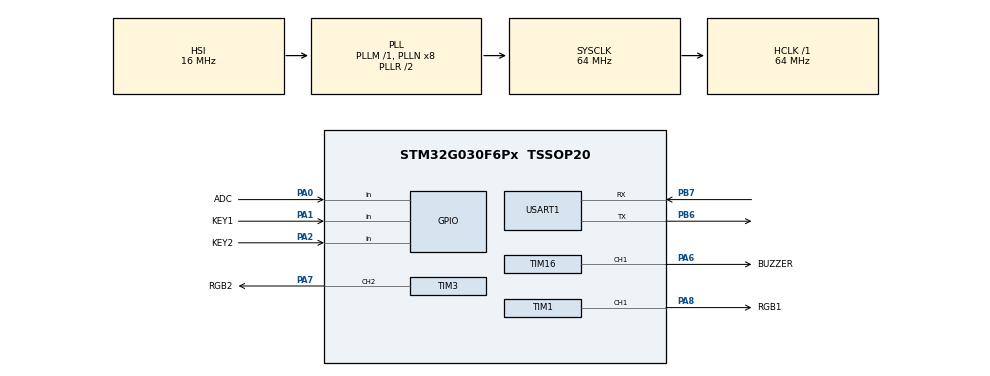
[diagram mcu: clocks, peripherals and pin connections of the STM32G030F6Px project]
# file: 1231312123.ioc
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Dma.Request0=TIM3_CH2
Dma.Request1=TIM1_CH1
Dma.TIM1_CH1.1.Direction=DMA_PERIPH_TO_MEMORY
Dma.TIM1_CH1.1.EventEnable=DISABLE
Dma.TIM1_CH1.1.Instance=DMA1_Channel2
Dma.TIM1_CH1.1.MemDataAlignment=DMA_MDATAALIGN_WORD
Dma.TIM1_CH1.1.MemInc=DMA_MINC_ENABLE
Dma.TIM1_CH1.1.Mode=DMA_NORMAL
Dma.TIM1_CH1.1.PeriphDataAlignment=DMA_PDATAALIGN_WORD
Dma.TIM1_CH1.1.PeriphInc=DMA_PINC_DISABLE
Dma.TIM1_CH1.1.Polarity=HAL_DMAMUX_REQ_GEN_RISING
Dma.TIM1_CH1.1.Priority=DMA_PRIORITY_LOW
Dma.TIM1_CH1.1.RequestNumber=1
Dma.TIM1_CH1.1.SignalID=NONE
Dma.TIM1_CH1.1.SyncEnable=DISABLE
Dma.TIM1_CH1.1.SyncPolarity=HAL_DMAMUX_SYNC_NO_EVENT
Dma.TIM1_CH1.1.SyncRequestNumber=1
Dma.TIM1_CH1.1.SyncSignalID=NONE
Dma.TIM3_CH2.0.Direction=DMA_PERIPH_TO_MEMORY
Dma.TIM3_CH2.0.EventEnable=DISABLE
Dma.TIM3_CH2.0.Instance=DMA1_Channel1
Dma.TIM3_CH2.0.MemDataAlignment=DMA_MDATAALIGN_WORD
Dma.TIM3_CH2.0.MemInc=DMA_MINC_ENABLE
Dma.TIM3_CH2.0.Mode=DMA_NORMAL
Dma.TIM3_CH2.0.PeriphDataAlignment=DMA_PDATAALIGN_WORD
Dma.TIM3_CH2.0.PeriphInc=DMA_PINC_DISABLE
Dma.TIM3_CH2.0.Polarity=HAL_DMAMUX_REQ_GEN_RISING
Dma.TIM3_CH2.0.Priority=DMA_PRIORITY_LOW
Dma.TIM3_CH2.0.RequestNumber=1
Dma.TIM3_CH2.0.SignalID=NONE
Dma.TIM3_CH2.0.SyncEnable=DISABLE
Dma.TIM3_CH2.0.SyncPolarity=HAL_DMAMUX_SYNC_NO_EVENT
Dma.TIM3_CH2.0.SyncRequestNumber=1
Dma.TIM3_CH2.0.SyncSignalID=NONE
Mcu.Family=STM32G0
Mcu.Name=STM32G030F6Px
Mcu.Package=TSSOP20
NVIC.DMA1_Channel1_IRQn=true\:0\:0\:false\:false\:true\:false\:true\:true
NVIC.DMA1_Channel2_3_IRQn=true\:0\:0\:false\:false\:true\:false\:true\:true
NVIC.TIM14_IRQn=true\:0\:0\:false\:false\:true\:true\:true\:true
PA0.GPIO_Label=ADC
PA0.GPIO_PuPd=GPIO_PULLUP
PA0.Signal=GPIO_Input
PA1.GPIO_Label=KEY1
PA1.GPIO_PuPd=GPIO_PULLUP
PA1.Signal=GPIO_Input
PA13.Mode=Serial_Wire
PA13.Signal=SYS_SWDIO
PA14-BOOT0.Mode=Serial_Wire
PA14-BOOT0.Signal=SYS_SWCLK
PA14-BOOT0__PA15.StandardMode=true
PA2.GPIO_Label=KEY2
PA2.GPIO_PuPd=GPIO_PULLUP
PA2.Signal=GPIO_Input
PA6.GPIO_Label=BUZZER
PA6.Signal=S_TIM16_CH1
PA7.GPIO_Label=RGB2
PA7.Signal=S_TIM3_CH2
PA8.GPIO_Label=RGB1
PA8.Signal=S_TIM1_CH1
PB0__PB1__PB2__PA8.StandardMode=true
PB3__PB4__PB5__PB6.StandardMode=true
PB6.Mode=Asynchronous
PB6.Signal=USART1_TX
PB7.Mode=Asynchronous
PB7.Signal=USART1_RX
PB7__PB8.StandardMode=true
PC14-OSC32_IN\ (PC14).Mode=HSE-External-Clock-Source
PC14-OSC32_IN\ (PC14).Signal=RCC_OSC_IN
PC14-OSC32_IN\ (PC14)__PB9.StandardMode=true
ProjectManager.HeapSize=0x200
ProjectManager.StackSize=0x400
ProjectManager.TargetToolchain=CMake
RCC.ADCFreq_Value=64000000
RCC.AHBFreq_Value=64000000
RCC.CortexFreq_Value=64000000
RCC.EXTERNAL_CLOCK_VALUE=12288000
RCC.HCLKFreq_Value=64000000
RCC.HSE_VALUE=8000000
RCC.HSI_VALUE=16000000
RCC.LSE_VALUE=32768
RCC.SYSCLKFreq_VALUE=64000000
RCC.SYSCLKSource=RCC_SYSCLKSOURCE_PLLCLK
RCC.VCOOutputFreq_Value=128000000
SH.S_TIM16_CH1.0=TIM16_CH1,PWM Generation1 CH1
SH.S_TIM1_CH1.0=TIM1_CH1,PWM Generation1 CH1
SH.S_TIM3_CH2.0=TIM3_CH2,PWM Generation2 CH2
TIM1.Channel-PWM\ Generation1\ CH1=TIM_CHANNEL_1
TIM1.Period=80
TIM14.Period=100-1
TIM14.Prescaler=320-1
TIM16.Channel=TIM_CHANNEL_1
TIM3.Channel-PWM\ Generation2\ CH2=TIM_CHANNEL_2
TIM3.Period=80
USART1.VirtualMode-Asynchronous=VM_ASYNC
VP_TIM14_VS_ClockSourceINT.Mode=Enable_Timer
VP_TIM16_VS_ClockSourceINT.Mode=Enable_Timer
board=custom

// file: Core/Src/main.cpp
/* USER CODE BEGIN Header */
/**
  ******************************************************************************
  * @file           : main.c
  * @brief          : Main program body
  ******************************************************************************
  * @attention
  *
  * Copyright (c) 2025 STMicroelectronics.
  * All rights reserved.
  *
  * This software is licensed under terms that can be found in the LICENSE file
  * in the root directory of this software component.
  * If no LICENSE file comes with this software, it is provided AS-IS.
  *
  ******************************************************************************
  */
/* USER CODE END Header */
#include "main.h"
#include "tim.h"
#include "usart.h"
#include "gpio.h"

/* USER CODE BEGIN Includes */
#include "ws2812.hpp"
/* USER CODE END Includes */

void SystemClock_Config(void);

int main(void)
{

  /* MCU Configuration--------------------------------------------------------*/

  /* Reset of all peripherals, Initializes the Flash interface and the Systick. */
  HAL_Init();

  /* Configure the system clock */
  SystemClock_Config();

  /* Initialize all configured peripherals */
  MX_GPIO_Init();
  MX_TIM1_Init();
  MX_TIM3_Init();
  MX_USART1_UART_Init();
  MX_TIM14_Init();
  MX_TIM16_Init();
  /* USER CODE BEGIN 2 */
  HAL_TIM_Base_Start_IT(&htim14);
  SOUND sound;
  /* USER CODE END 2 */

  /* Infinite loop */
  while (1)
  {

    /* USER CODE BEGIN 3 */
            if (sound.Sound_State())
    {
        black.Send_Data();
        HAL_Delay(20);
    }
  }
  /* USER CODE END 3 */
}

void SystemClock_Config(void)
{
  RCC_OscInitTypeDef RCC_OscInitStruct = {0};
  RCC_ClkInitTypeDef RCC_ClkInitStruct = {0};

  /** Configure the main internal regulator output voltage
  */
  HAL_PWREx_ControlVoltageScaling(PWR_REGULATOR_VOLTAGE_SCALE1);

  /** Initializes the RCC Oscillators according to the specified parameters
  * in the RCC_OscInitTypeDef structure.
  */
  RCC_OscInitStruct.OscillatorType = RCC_OSCILLATORTYPE_HSI;
  RCC_OscInitStruct.HSIState = RCC_HSI_ON;
  RCC_OscInitStruct.HSIDiv = RCC_HSI_DIV1;
  RCC_OscInitStruct.HSICalibrationValue = RCC_HSICALIBRATION_DEFAULT;
  RCC_OscInitStruct.PLL.PLLState = RCC_PLL_ON;
  RCC_OscInitStruct.PLL.PLLSource = RCC_PLLSOURCE_HSI;
  RCC_OscInitStruct.PLL.PLLM = RCC_PLLM_DIV1;
  RCC_OscInitStruct.PLL.PLLN = 8;
  RCC_OscInitStruct.PLL.PLLP = RCC_PLLP_DIV2;
  RCC_OscInitStruct.PLL.PLLR = RCC_PLLR_DIV2;
  if (HAL_RCC_OscConfig(&RCC_OscInitStruct) != HAL_OK)
  {
    Error_Handler();
  }

  /** Initializes the CPU, AHB and APB buses clocks
  */
  RCC_ClkInitStruct.ClockType = RCC_CLOCKTYPE_HCLK|RCC_CLOCKTYPE_SYSCLK
                              |RCC_CLOCKTYPE_PCLK1;
  RCC_ClkInitStruct.SYSCLKSource = RCC_SYSCLKSOURCE_PLLCLK;
  RCC_ClkInitStruct.AHBCLKDivider = RCC_SYSCLK_DIV1;
  RCC_ClkInitStruct.APB1CLKDivider = RCC_HCLK_DIV1;

  if (HAL_RCC_ClockConfig(&RCC_ClkInitStruct, FLASH_LATENCY_2) != HAL_OK)
  {
    Error_Handler();
  }
}

void Error_Handler(void)
{
  __disable_irq();
  while (1)
  {
  }
}
